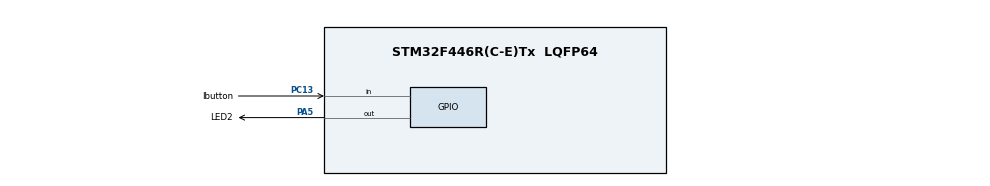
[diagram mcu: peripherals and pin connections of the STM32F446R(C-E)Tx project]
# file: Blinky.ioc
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Mcu.Family=STM32F4
Mcu.Name=STM32F446R(C-E)Tx
Mcu.Package=LQFP64
NVIC.PriorityGroup=NVIC_PRIORITYGROUP_4
NVIC.TIM8_TRG_COM_TIM14_IRQn=true\:0\:0\:false\:false\:true\:true\:true
PA5.GPIO_Label=LED2
PA5.GPIO_ModeDefaultOutputPP=GPIO_MODE_OUTPUT_PP
PA5.GPIO_Speed=GPIO_SPEED_FREQ_LOW
PA5.PinState=GPIO_PIN_SET
PA5.Signal=GPIO_Output
PC13.GPIO_Label=Ibutton
PC13.GPIO_PuPd=GPIO_PULLUP
PC13.Signal=GPIO_Input
ProjectManager.HeapSize=0x200
ProjectManager.StackSize=0x400
ProjectManager.TargetToolchain=STM32CubeIDE
RCC.AHBFreq_Value=16000000
RCC.APB1Freq_Value=16000000
RCC.APB1TimFreq_Value=16000000
RCC.APB2Freq_Value=16000000
RCC.APB2TimFreq_Value=16000000
RCC.CortexFreq_Value=16000000
RCC.HCLKFreq_Value=16000000
RCC.USBFreq_Value=96000000
RCC.VCOOutputFreq_Value=192000000
TIM14.Period=9999
TIM14.Prescaler=1599
VP_TIM14_VS_ClockSourceINT.Mode=Enable_Timer
board=custom

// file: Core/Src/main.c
/* USER CODE BEGIN Header */
/**
  ******************************************************************************
  * @file           : main.c
  * @brief          : Main program body
  ******************************************************************************
  * @attention
  *
  * <h2><center>&copy; Copyright (c) 2021 STMicroelectronics.
  * All rights reserved.</center></h2>
  *
  * This software component is licensed by ST under BSD 3-Clause license,
  * the "License"; You may not use this file except in compliance with the
  * License. You may obtain a copy of the License at:
  *                        opensource.org/licenses/BSD-3-Clause
  *
  ******************************************************************************
  */
/* USER CODE END Header */
#include "main.h"

/* USER CODE BEGIN Includes */
#define LOW 0
#define HIGH 1
#define DEB_THRESHOLD 10

/* USER CODE END Includes */

TIM_HandleTypeDef htim14;

/* USER CODE BEGIN PV */
/*volatile unsigned short B_STATE=LOW;
volatile unsigned short LAST_B_STATE=LOW;
volatile unsigned short L_STATE=LOW;
volatile unsigned short B_PRESS_CONF=LOW;
volatile unsigned short B_REL_CONF=LOW;
volatile unsigned short B_PRESS=LOW;*/

/* USER CODE END PV */

void SystemClock_Config(void);
static void MX_GPIO_Init(void);
static void MX_TIM14_Init(void);

int main(void)
{
  /* USER CODE BEGIN 1 */
 //uint16_t timer_val;
  /* USER CODE END 1 */

  /* MCU Configuration--------------------------------------------------------*/

  /* Reset of all peripherals, Initializes the Flash interface and the Systick. */
  HAL_Init();

  /* Configure the system clock */
  SystemClock_Config();

  /* Initialize all configured peripherals */
  MX_GPIO_Init();
  MX_TIM14_Init();
  /* USER CODE BEGIN 2 */
  HAL_TIM_Base_Start_IT(&htim14);
 // timer_val = __HAL_TIM_GET_COUNTER(&htim14);

  /* USER CODE END 2 */

  /* Infinite loop */
  /* USER CODE BEGIN WHILE */
  // GPIO_PIN_SET   => 1
  // GPIO_PIN_RESET => 0
 // static unsigned short pin_state = 1;
  //static unsigned short GPIO_PIN_RESET=0;
  //static unsigned short GPIO_PIN_SET=1;
  	  	// HAL_GPIO_WritePin(LED2_GPIO_Port, LED2_Pin,GPIO_PIN_SET);
  		 //LAST_B_STATE = HAL_GPIO_ReadPin(Ibutton_GPIO_Port, Ibutton_Pin);
  		 //L_STATE = HAL_GPIO_ReadPin(LED2_GPIO_Port,LED2_Pin);
  		 //B_PRESS= HAL_GPIO_ReadPin(Ibutton_GPIO_Port, Ibutton_Pin);
  while (1)
  {
    /* USER CODE END WHILE */

    /* USER CODE BEGIN 3 */
	  /*if (__HAL_TIM_GET_COUNTER(&htim14) - timer_val >= 10000)
	      {
		  HAL_GPIO_TogglePin(LED2_GPIO_Port,LED2_Pin);
	        timer_val = __HAL_TIM_GET_COUNTER(&htim14);
	      }*/
	  //pin_state = !pin_state;
	  // write pin state
	  // NOTE: You can in turn use HAL_GPIO_TogglePin
	  //HAL_GPIO_WritePin(LED2_GPIO_Port, LED2_Pin, pin_state);
	  // synchronous delay for 2000 ms
	  //HAL_Delay(1000);
#if 0
		 B_STATE = HAL_GPIO_ReadPin(Ibutton_GPIO_Port, Ibutton_Pin);
			 	  if(B_STATE==LOW)
			 	  {
			 		  B_PRESS_CONF++;
			 		  B_REL_CONF=LOW;
			 		  if(B_PRESS_CONF >= DEB_THRESHOLD)
			 		  {
			 		    B_PRESS=LOW;
			 		  }
			 	  }
			 	  else
			 	  {
			 	  	  B_REL_CONF++;
			 	  	  B_PRESS_CONF=LOW;
			 	  	  if(B_REL_CONF >= DEB_THRESHOLD)
			 	  	  {
			 	  		 B_PRESS=HIGH;
			 	  	  }
			 	  }

			 	  if(B_PRESS != LAST_B_STATE)
			 	  {
			 		  LAST_B_STATE=B_PRESS;
			 	  	  if(B_PRESS==LOW)
			 	  	  {
			 	  		  L_STATE = (L_STATE==HIGH)?LOW:HIGH;
			 	  		  HAL_GPIO_WritePin(LED2_GPIO_Port, LED2_Pin,L_STATE);
			 	  	  }
			 	  }
#endif

#if 0
	 // if(HAL_GPIO_ReadPin(Ibutton_GPIO_Port, Ibutton_Pin)==GPIO_PIN_SET)  //Check if button pressed
	 // HAL_GPIO_WritePin(LED2_GPIO_Port, LED2_Pin,GPIO_PIN_RESET);               //If pressed Led Switch On
	 // else
     // HAL_GPIO_WritePin(LED2_GPIO_Port, LED2_Pin,GPIO_PIN_SET);          //Else Led Switch Off
#endif
  }
  /* USER CODE END 3 */
}

void SystemClock_Config(void)
{
  RCC_OscInitTypeDef RCC_OscInitStruct = {0};
  RCC_ClkInitTypeDef RCC_ClkInitStruct = {0};

  /** Configure the main internal regulator output voltage
  */
  __HAL_RCC_PWR_CLK_ENABLE();
  __HAL_PWR_VOLTAGESCALING_CONFIG(PWR_REGULATOR_VOLTAGE_SCALE3);
  /** Initializes the RCC Oscillators according to the specified parameters
  * in the RCC_OscInitTypeDef structure.
  */
  RCC_OscInitStruct.OscillatorType = RCC_OSCILLATORTYPE_HSI;
  RCC_OscInitStruct.HSIState = RCC_HSI_ON;
  RCC_OscInitStruct.HSICalibrationValue = RCC_HSICALIBRATION_DEFAULT;
  RCC_OscInitStruct.PLL.PLLState = RCC_PLL_NONE;
  if (HAL_RCC_OscConfig(&RCC_OscInitStruct) != HAL_OK)
  {
    Error_Handler();
  }
  /** Initializes the CPU, AHB and APB buses clocks
  */
  RCC_ClkInitStruct.ClockType = RCC_CLOCKTYPE_HCLK|RCC_CLOCKTYPE_SYSCLK
                              |RCC_CLOCKTYPE_PCLK1|RCC_CLOCKTYPE_PCLK2;
  RCC_ClkInitStruct.SYSCLKSource = RCC_SYSCLKSOURCE_HSI;
  RCC_ClkInitStruct.AHBCLKDivider = RCC_SYSCLK_DIV1;
  RCC_ClkInitStruct.APB1CLKDivider = RCC_HCLK_DIV1;
  RCC_ClkInitStruct.APB2CLKDivider = RCC_HCLK_DIV1;

  if (HAL_RCC_ClockConfig(&RCC_ClkInitStruct, FLASH_LATENCY_0) != HAL_OK)
  {
    Error_Handler();
  }
}

static void MX_TIM14_Init(void)
{

  htim14.Instance = TIM14;
  htim14.Init.Prescaler = 1599;
  htim14.Init.CounterMode = TIM_COUNTERMODE_UP;
  htim14.Init.Period = 9999;
  htim14.Init.ClockDivision = TIM_CLOCKDIVISION_DIV1;
  htim14.Init.AutoReloadPreload = TIM_AUTORELOAD_PRELOAD_DISABLE;
  if (HAL_TIM_Base_Init(&htim14) != HAL_OK)
  {
    Error_Handler();
  }

}

static void MX_GPIO_Init(void)
{
  GPIO_InitTypeDef GPIO_InitStruct = {0};

  /* GPIO Ports Clock Enable */
  __HAL_RCC_GPIOC_CLK_ENABLE();
  __HAL_RCC_GPIOA_CLK_ENABLE();

  /*Configure GPIO pin Output Level */
  HAL_GPIO_WritePin(LED2_GPIO_Port, LED2_Pin, GPIO_PIN_SET);

  /*Configure GPIO pin : Ibutton_Pin */
  GPIO_InitStruct.Pin = Ibutton_Pin;
  GPIO_InitStruct.Mode = GPIO_MODE_INPUT;
  GPIO_InitStruct.Pull = GPIO_PULLUP;
  HAL_GPIO_Init(Ibutton_GPIO_Port, &GPIO_InitStruct);

  /*Configure GPIO pin : LED2_Pin */
  GPIO_InitStruct.Pin = LED2_Pin;
  GPIO_InitStruct.Mode = GPIO_MODE_OUTPUT_PP;
  GPIO_InitStruct.Pull = GPIO_NOPULL;
  GPIO_InitStruct.Speed = GPIO_SPEED_FREQ_LOW;
  HAL_GPIO_Init(LED2_GPIO_Port, &GPIO_InitStruct);

}

/* USER CODE BEGIN 4 */
//callback function
void HAL_TIM_PeriodElapsedCallback(TIM_HandleTypeDef *htim)
{
	if(htim == &htim14)
	{
		 HAL_GPIO_TogglePin(LED2_GPIO_Port,LED2_Pin);
	}
}

/* USER CODE END 4 */

void Error_Handler(void)
{
  __disable_irq();
  while (1)
  {
  }
}

ASSERT */

/************************ (C) COPYRIGHT STMicroelectronics *****END OF FILE****/
